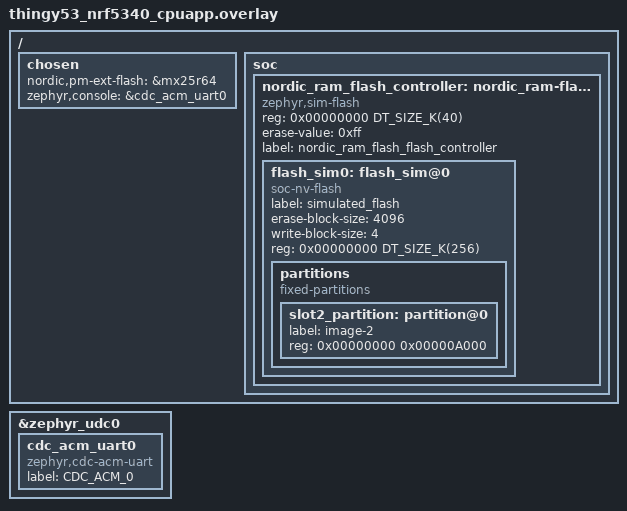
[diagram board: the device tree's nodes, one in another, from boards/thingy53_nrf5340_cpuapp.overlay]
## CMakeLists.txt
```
#
# Copyright (c) 2019 Nordic Semiconductor ASA
#
# SPDX-License-Identifier: LicenseRef-Nordic-5-Clause
#
cmake_minimum_required(VERSION 3.20.0)

set(PM_STATIC_YML_FILE
  ${CMAKE_CURRENT_SOURCE_DIR}/boards/pm_static_${BOARD}.yml
  )

find_package(Zephyr REQUIRED HINTS $ENV{ZEPHYR_BASE})
project(NONE)

# NORDIC SDK APP START
target_sources(app PRIVATE
	src/main.c
	src/model_handler.c)
target_include_directories(app PRIVATE include)

# Preinitialization related to Thingy:53 DFU
target_sources_ifdef(CONFIG_BOARD_THINGY53_NRF5340_CPUAPP app PRIVATE
  boards/thingy53.c
)
target_sources_ifdef(CONFIG_BOARD_THINGY53_NRF5340_CPUAPP_NS app PRIVATE
  boards/thingy53.c
)

# NORDIC SDK APP END
```

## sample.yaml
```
sample:
  name: Bluetooth mesh light
  description: Bluetooth mesh light sample
tests:
  samples.bluetooth.mesh.light:
    build_only: true
    platform_allow: nrf52dk_nrf52832 nrf52840dk_nrf52840 nrf5340dk_nrf5340_cpuapp
      nrf5340dk_nrf5340_cpuapp_ns thingy53_nrf5340_cpuapp thingy53_nrf5340_cpuapp_ns
      nrf21540dk_nrf52840
    tags: bluetooth ci_build
    integration_platforms:
      - nrf52dk_nrf52832
      - nrf52840dk_nrf52840
      - nrf5340dk_nrf5340_cpuapp
      - nrf5340dk_nrf5340_cpuapp_ns
      - thingy53_nrf5340_cpuapp
      - thingy53_nrf5340_cpuapp_ns
      - nrf21540dk_nrf52840
```

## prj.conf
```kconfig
#
# Copyright (c) 2019 Nordic Semiconductor ASA
#
# SPDX-License-Identifier: LicenseRef-Nordic-5-Clause
#
CONFIG_NCS_SAMPLES_DEFAULTS=y

# General configuration
CONFIG_SYSTEM_WORKQUEUE_STACK_SIZE=2048
CONFIG_FLASH=y
CONFIG_FLASH_MAP=y
CONFIG_NVS=y
CONFIG_SETTINGS=y
CONFIG_HWINFO=y
CONFIG_DK_LIBRARY=y

# Bluetooth configuration
CONFIG_BT=y
CONFIG_BT_COMPANY_ID=0x0059
CONFIG_BT_DEVICE_NAME="Mesh Light"
CONFIG_BT_L2CAP_TX_MTU=69
CONFIG_BT_L2CAP_TX_BUF_COUNT=8
CONFIG_BT_OBSERVER=y
CONFIG_BT_PERIPHERAL=y
CONFIG_BT_SETTINGS=y

# Disable unused Bluetooth features
CONFIG_BT_CTLR_DUP_FILTER_LEN=0
CONFIG_BT_CTLR_LE_ENC=n
CONFIG_BT_DATA_LEN_UPDATE=n
CONFIG_BT_PHY_UPDATE=n
CONFIG_BT_CTLR_CHAN_SEL_2=n
CONFIG_BT_CTLR_MIN_USED_CHAN=n
CONFIG_BT_CTLR_PRIVACY=n

# Bluetooth mesh configuration
CONFIG_BT_MESH=y
CONFIG_BT_MESH_RELAY=y
CONFIG_BT_MESH_FRIEND=y
CONFIG_BT_MESH_ADV_BUF_COUNT=13
CONFIG_BT_MESH_TX_SEG_MAX=10
CONFIG_BT_MESH_PB_GATT=y
CONFIG_BT_MESH_GATT_PROXY=y
CONFIG_BT_MESH_PROXY_USE_DEVICE_NAME=y
CONFIG_BT_MESH_DK_PROV=y

# Bluetooth mesh models
CONFIG_BT_MESH_ONOFF_SRV=y
```

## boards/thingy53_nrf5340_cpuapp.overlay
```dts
/*
 * Copyright (c) 2021 Nordic Semiconductor ASA
 *
 * SPDX-License-Identifier: LicenseRef-Nordic-5-Clause
 */

/ {
	chosen {
		nordic,pm-ext-flash = &mx25r64;
	};
};

/*
 * This section is used to enable a partition which is used through the flash API
 * but which is in reality stored in RAM. This is done to load data from
 * external flash to the network core. Since the network core cannot access
 * the external flash directly, the data is buffered in RAM before being
 * copied by the network core to the network core flash.
 *
 * The partition must be enabled by the application configuration to prevent
 * bus faults when mcumgr tries to access simulated partition with network core
 * image data.
 */

/ {
	soc {
		/* Add a flash controller which has the compatible
		 * 'zephyr,sim-flash'. This will ensure that the flash
		 * simulator can use it. None of the other properties in this
		 * node is used for anything.
		 */
		nordic_ram_flash_controller: nordic_ram-flash-controller@0 {
			compatible = "zephyr,sim-flash";
			reg = <0x00000000 DT_SIZE_K(40)>;
			#address-cells = <1>;
			#size-cells = <1>;
			erase-value = <0xff>;
			label = "nordic_ram_flash_flash_controller";

			/* This node label must match that used in the flash
			 * simulator.
			 */
			flash_sim0: flash_sim@0 {
				status = "okay";
				compatible = "soc-nv-flash";
				label = "simulated_flash";
				erase-block-size = <4096>;
				write-block-size = <4>;
				reg = <0x00000000 DT_SIZE_K(256)>;

				partitions {
					compatible = "fixed-partitions";
					#address-cells = <1>;
					#size-cells = <1>;

					/* This partition must be defined for
					 * MCUboot to find the partition ID
					 * of the primary slot for image 1,
					 * which is stored in this partition.
					 */
					slot2_partition: partition@0 {
						label = "image-2";
						reg = <0x00000000 0x00000A000>;
					};
				};
			};
		};
	};

	chosen {
		zephyr,console = &cdc_acm_uart0;
	};
};

&zephyr_udc0 {
	cdc_acm_uart0: cdc_acm_uart0 {
		compatible = "zephyr,cdc-acm-uart";
		label = "CDC_ACM_0";
	};
};
```

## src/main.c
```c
/*
 * Copyright (c) 2019 Nordic Semiconductor ASA
 *
 * SPDX-License-Identifier: LicenseRef-Nordic-5-Clause
 */

/** @file
 *  @brief Nordic mesh light sample
 */
#include <bluetooth/bluetooth.h>
#include <bluetooth/mesh/models.h>
#include <bluetooth/mesh/dk_prov.h>
#include <dk_buttons_and_leds.h>
#include "model_handler.h"

static void bt_ready(int err)
{
	if (err) {
		printk("Bluetooth init failed (err %d)\n", err);
		return;
	}

	printk("Bluetooth initialized\n");

	dk_leds_init();
	dk_buttons_init(NULL);

	err = bt_mesh_init(bt_mesh_dk_prov_init(), model_handler_init());
	if (err) {
		printk("Initializing mesh failed (err %d)\n", err);
		return;
	}

	if (IS_ENABLED(CONFIG_SETTINGS)) {
		settings_load();
	}

	/* This will be a no-op if settings_load() loaded provisioning info */
	bt_mesh_prov_enable(BT_MESH_PROV_ADV | BT_MESH_PROV_GATT);

	printk("Mesh initialized\n");
}

void main(void)
{
	int err;

	printk("Initializing...\n");

	err = bt_enable(bt_ready);
	if (err) {
		printk("Bluetooth init failed (err %d)\n", err);
	}
}
```

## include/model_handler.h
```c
/*
 * Copyright (c) 2019 Nordic Semiconductor ASA
 *
 * SPDX-License-Identifier: LicenseRef-Nordic-5-Clause
 */

/**
 * @file
 * @brief Model handler
 */

#ifndef MODEL_HANDLER_H__
#define MODEL_HANDLER_H__

#include <bluetooth/mesh.h>

#ifdef __cplusplus
extern "C" {
#endif

const struct bt_mesh_comp *model_handler_init(void);

#ifdef __cplusplus
}
#endif

#endif /* MODEL_HANDLER_H__ */
```

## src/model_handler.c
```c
/*
 * Copyright (c) 2019 Nordic Semiconductor ASA
 *
 * SPDX-License-Identifier: LicenseRef-Nordic-5-Clause
 */

#include <bluetooth/bluetooth.h>
#include <bluetooth/mesh/models.h>
#include <dk_buttons_and_leds.h>
#include "model_handler.h"

static void led_set(struct bt_mesh_onoff_srv *srv, struct bt_mesh_msg_ctx *ctx,
		    const struct bt_mesh_onoff_set *set,
		    struct bt_mesh_onoff_status *rsp);

static void led_get(struct bt_mesh_onoff_srv *srv, struct bt_mesh_msg_ctx *ctx,
		    struct bt_mesh_onoff_status *rsp);

static const struct bt_mesh_onoff_srv_handlers onoff_handlers = {
	.set = led_set,
	.get = led_get,
};

struct led_ctx {
	struct bt_mesh_onoff_srv srv;
	struct k_work_delayable work;
	uint32_t remaining;
	bool value;
};

static struct led_ctx led_ctx[] = {
#if DT_NODE_EXISTS(DT_ALIAS(led0))
	{ .srv = BT_MESH_ONOFF_SRV_INIT(&onoff_handlers) },
#endif
#if DT_NODE_EXISTS(DT_ALIAS(led1))
	{ .srv = BT_MESH_ONOFF_SRV_INIT(&onoff_handlers) },
#endif
#if DT_NODE_EXISTS(DT_ALIAS(led2))
	{ .srv = BT_MESH_ONOFF_SRV_INIT(&onoff_handlers) },
#endif
#if DT_NODE_EXISTS(DT_ALIAS(led3))
	{ .srv = BT_MESH_ONOFF_SRV_INIT(&onoff_handlers) },
#endif
};

static void led_transition_start(struct led_ctx *led)
{
	int led_idx = led - &led_ctx[0];

	/* As long as the transition is in progress, the onoff
	 * state is "on":
	 */
	dk_set_led(led_idx, true);
	k_work_reschedule(&led->work, K_MSEC(led->remaining));
	led->remaining = 0;
}

static void led_status(struct led_ctx *led, struct bt_mesh_onoff_status *status)
{
	/* Do not include delay in the remaining time. */
	status->remaining_time = led->remaining ? led->remaining :
		k_ticks_to_ms_ceil32(k_work_delayable_remaining_get(&led->work));
	status->target_on_off = led->value;
	/* As long as the transition is in progress, the onoff state is "on": */
	status->present_on_off = led->value || status->remaining_time;
}

static void led_set(struct bt_mesh_onoff_srv *srv, struct bt_mesh_msg_ctx *ctx,
		    const struct bt_mesh_onoff_set *set,
		    struct bt_mesh_onoff_status *rsp)
{
	struct led_ctx *led = CONTAINER_OF(srv, struct led_ctx, srv);
	int led_idx = led - &led_ctx[0];

	if (set->on_off == led->value) {
		goto respond;
	}

	led->value = set->on_off;
	if (!bt_mesh_model_transition_time(set->transition)) {
		led->remaining = 0;
		dk_set_led(led_idx, set->on_off);
		goto respond;
	}

	led->remaining = set->transition->time;

	if (set->transition->delay) {
		k_work_reschedule(&led->work, K_MSEC(set->transition->delay));
	} else {
		led_transition_start(led);
	}

respond:
	if (rsp) {
		led_status(led, rsp);
	}
}

static void led_get(struct bt_mesh_onoff_srv *srv, struct bt_mesh_msg_ctx *ctx,
		    struct bt_mesh_onoff_status *rsp)
{
	struct led_ctx *led = CONTAINER_OF(srv, struct led_ctx, srv);

	led_status(led, rsp);
}

static void led_work(struct k_work *work)
{
	struct led_ctx *led = CONTAINER_OF(work, struct led_ctx, work.work);
	int led_idx = led - &led_ctx[0];

	if (led->remaining) {
		led_transition_start(led);
	} else {
		dk_set_led(led_idx, led->value);

		/* Publish the new value at the end of the transition */
		struct bt_mesh_onoff_status status;

		led_status(led, &status);
		bt_mesh_onoff_srv_pub(&led->srv, NULL, &status);
	}
}

/* Set up a repeating delayed work to blink the DK's LEDs when attention is
 * requested.
 */
static struct k_work_delayable attention_blink_work;
static bool attention;

static void attention_blink(struct k_work *work)
{
	static int idx;
	const uint8_t pattern[] = {
#if DT_NODE_EXISTS(DT_ALIAS(led0))
		BIT(0),
#endif
#if DT_NODE_EXISTS(DT_ALIAS(led1))
		BIT(1),
#endif
#if DT_NODE_EXISTS(DT_ALIAS(led2))
		BIT(2),
#endif
#if DT_NODE_EXISTS(DT_ALIAS(led3))
		BIT(3),
#endif
	};

	if (attention) {
		dk_set_leds(pattern[idx++ % ARRAY_SIZE(pattern)]);
		k_work_reschedule(&attention_blink_work, K_MSEC(30));
	} else {
		dk_set_leds(DK_NO_LEDS_MSK);
	}
}

static void attention_on(struct bt_mesh_model *mod)
{
	attention = true;
	k_work_reschedule(&attention_blink_work, K_NO_WAIT);
}

static void attention_off(struct bt_mesh_model *mod)
{
	/* Will stop rescheduling blink timer */
	attention = false;
}

static const struct bt_mesh_health_srv_cb health_srv_cb = {
	.attn_on = attention_on,
	.attn_off = attention_off,
};

static struct bt_mesh_health_srv health_srv = {
	.cb = &health_srv_cb,
};

BT_MESH_HEALTH_PUB_DEFINE(health_pub, 0);

static struct bt_mesh_elem elements[] = {
#if DT_NODE_EXISTS(DT_ALIAS(led0))
	BT_MESH_ELEM(
		1, BT_MESH_MODEL_LIST(
			BT_MESH_MODEL_CFG_SRV,
			BT_MESH_MODEL_HEALTH_SRV(&health_srv, &health_pub),
			BT_MESH_MODEL_ONOFF_SRV(&led_ctx[0].srv)),
		BT_MESH_MODEL_NONE),
#endif
#if DT_NODE_EXISTS(DT_ALIAS(led1))
	BT_MESH_ELEM(
		2, BT_MESH_MODEL_LIST(BT_MESH_MODEL_ONOFF_SRV(&led_ctx[1].srv)),
		BT_MESH_MODEL_NONE),
#endif
#if DT_NODE_EXISTS(DT_ALIAS(led2))
	BT_MESH_ELEM(
		3, BT_MESH_MODEL_LIST(BT_MESH_MODEL_ONOFF_SRV(&led_ctx[2].srv)),
		BT_MESH_MODEL_NONE),
#endif
#if DT_NODE_EXISTS(DT_ALIAS(led3))
	BT_MESH_ELEM(
		4, BT_MESH_MODEL_LIST(BT_MESH_MODEL_ONOFF_SRV(&led_ctx[3].srv)),
		BT_MESH_MODEL_NONE),
#endif
};

static const struct bt_mesh_comp comp = {
	.cid = CONFIG_BT_COMPANY_ID,
	.elem = elements,
	.elem_count = ARRAY_SIZE(elements),
};

const struct bt_mesh_comp *model_handler_init(void)
{
	k_work_init_delayable(&attention_blink_work, attention_blink);

	for (int i = 0; i < ARRAY_SIZE(led_ctx); ++i) {
		k_work_init_delayable(&led_ctx[i].work, led_work);
	}

	return &comp;
}
```
